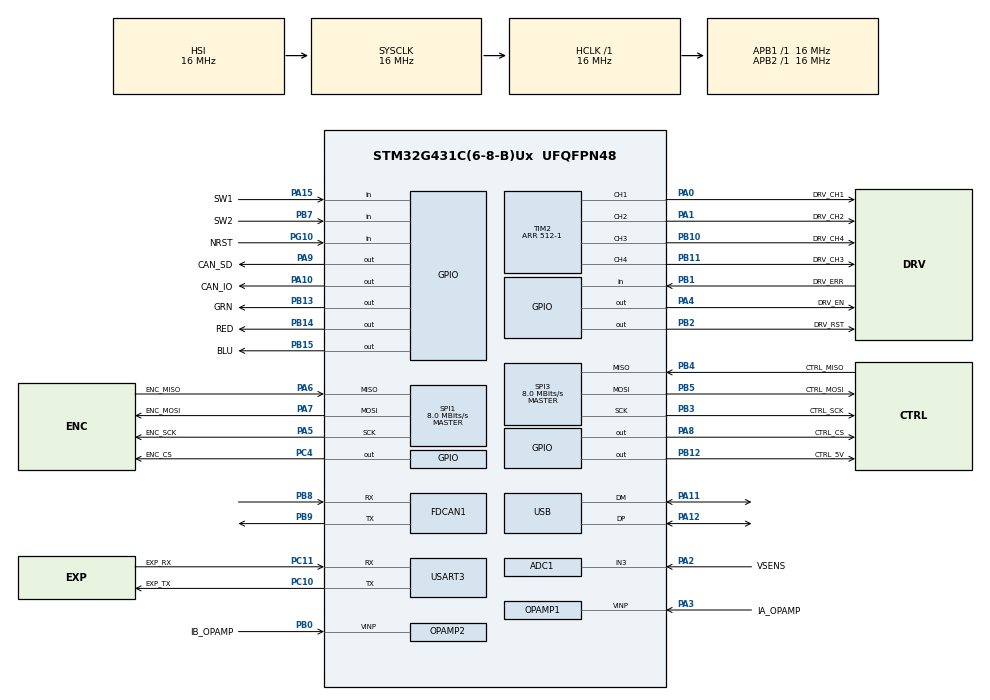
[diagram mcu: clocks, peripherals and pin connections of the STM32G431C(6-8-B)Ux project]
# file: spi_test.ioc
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ADC1.Channel-0\#ChannelRegularConversion=ADC_CHANNEL_3
ADC1.NbrOfConversionFlag=1
ADC1.OffsetNumber-0\#ChannelRegularConversion=ADC_OFFSET_NONE
ADC1.Rank-0\#ChannelRegularConversion=1
ADC1.SamplingTime-0\#ChannelRegularConversion=ADC_SAMPLETIME_2CYCLES_5
ADC1.master=1
FDCAN1.CalculateBaudRateNominal=200000
FDCAN1.CalculateTimeBitNominal=5000
FDCAN1.CalculateTimeQuantumNominal=1000.0
Mcu.Family=STM32G4
Mcu.Name=STM32G431C(6-8-B)Ux
Mcu.Package=UFQFPN48
NVIC.PriorityGroup=NVIC_PRIORITYGROUP_4
PA0.GPIO_Label=DRV_CH1
PA0.Signal=S_TIM2_CH1
PA1.GPIO_Label=DRV_CH2
PA1.Signal=S_TIM2_CH2
PA10.GPIO_Label=CAN_IO
PA10.Signal=GPIO_Output
PA11.Mode=Device
PA11.Signal=USB_DM
PA12.Mode=Device
PA12.Signal=USB_DP
PA13.GPIO_Label=SWDIO
PA13.Mode=Serial_Wire
PA13.Signal=SYS_JTMS-SWDIO
PA14.GPIO_Label=SWCLK
PA14.Mode=Serial_Wire
PA14.Signal=SYS_JTCK-SWCLK
PA15.GPIO_Label=SW1
PA15.Signal=GPIO_Input
PA2.GPIO_Label=VSENS
PA2.Mode=IN3-Single-Ended
PA2.Signal=ADC1_IN3
PA3.GPIO_Label=IA_OPAMP
PA3.Mode=Follower_Internally_Connected
PA3.Signal=OPAMP1_VINP
PA4.GPIO_Label=DRV_EN
PA4.PinState=GPIO_PIN_SET
PA4.Signal=GPIO_Output
PA5.GPIO_Label=ENC_SCK
PA5.Mode=Full_Duplex_Master
PA5.Signal=SPI1_SCK
PA6.GPIO_Label=ENC_MISO
PA6.Mode=Full_Duplex_Master
PA6.Signal=SPI1_MISO
PA7.GPIO_Label=ENC_MOSI
PA7.Mode=Full_Duplex_Master
PA7.Signal=SPI1_MOSI
PA8.GPIO_Label=CTRL_CS
PA8.Signal=GPIO_Output
PA9.GPIO_Label=CAN_SD
PA9.Signal=GPIO_Output
PB0.GPIO_Label=IB_OPAMP
PB0.Mode=Follower_Internally_Connected
PB0.Signal=OPAMP2_VINP
PB1.GPIO_Label=DRV_ERR
PB1.Signal=GPIO_Input
PB10.GPIO_Label=DRV_CH4
PB10.Signal=S_TIM2_CH3
PB11.GPIO_Label=DRV_CH3
PB11.Signal=S_TIM2_CH4
PB12.GPIO_Label=CTRL_5V
PB12.Signal=GPIO_Output
PB13.GPIO_Label=GRN
PB13.Signal=GPIO_Output
PB14.GPIO_Label=RED
PB14.Signal=GPIO_Output
PB15.GPIO_Label=BLU
PB15.Signal=GPIO_Output
PB2.GPIO_Label=DRV_RST
PB2.PinState=GPIO_PIN_SET
PB2.Signal=GPIO_Output
PB3.GPIO_Label=CTRL_SCK
PB3.Mode=Full_Duplex_Master
PB3.Signal=SPI3_SCK
PB4.GPIO_Label=CTRL_MISO
PB4.Mode=Full_Duplex_Master
PB4.Signal=SPI3_MISO
PB5.GPIO_Label=CTRL_MOSI
PB5.Mode=Full_Duplex_Master
PB5.Signal=SPI3_MOSI
PB7.GPIO_Label=SW2
PB7.Signal=GPIO_Input
PB8-BOOT0.Mode=FDCAN_Activate
PB8-BOOT0.Signal=FDCAN1_RX
PB9.Mode=FDCAN_Activate
PB9.Signal=FDCAN1_TX
PC10.GPIO_Label=EXP_TX
PC10.Mode=Asynchronous
PC10.Signal=USART3_TX
PC11.GPIO_Label=EXP_RX
PC11.Mode=Asynchronous
PC11.Signal=USART3_RX
PC4.GPIO_Label=ENC_CS
PC4.Signal=GPIO_Output
PF0-OSC_IN.GPIO_Label=HSE_IN
PF0-OSC_IN.Mode=HSE-External-Oscillator
PF0-OSC_IN.Signal=RCC_OSC_IN
PF1-OSC_OUT.GPIO_Label=HSE_OUT
PF1-OSC_OUT.Mode=HSE-External-Oscillator
PF1-OSC_OUT.Signal=RCC_OSC_OUT
PG10-NRST.GPIO_Label=NRST
PG10-NRST.Signal=GPIO_Input
ProjectManager.HeapSize=0x200
ProjectManager.StackSize=0x400
ProjectManager.TargetToolchain=STM32CubeIDE
RCC.ADC12Freq_Value=16000000
RCC.AHBFreq_Value=16000000
RCC.APB1Freq_Value=16000000
RCC.APB1TimFreq_Value=16000000
RCC.APB2Freq_Value=16000000
RCC.APB2TimFreq_Value=16000000
RCC.CortexFreq_Value=16000000
RCC.EXTERNAL_CLOCK_VALUE=12288000
RCC.HCLKFreq_Value=16000000
RCC.HSE_VALUE=8000000
RCC.HSI48_VALUE=48000000
RCC.HSI_VALUE=16000000
RCC.LSE_VALUE=32768
RCC.PLLN=12
RCC.PLLQ=RCC_PLLQ_DIV4
RCC.SYSCLKFreq_VALUE=16000000
RCC.USBFreq_Value=48000000
RCC.VCOOutputFreq_Value=192000000
SH.S_TIM2_CH1.0=TIM2_CH1,PWM Generation1 CH1
SH.S_TIM2_CH2.0=TIM2_CH2,PWM Generation2 CH2
SH.S_TIM2_CH3.0=TIM2_CH3,PWM Generation3 CH3
SH.S_TIM2_CH4.0=TIM2_CH4,PWM Generation4 CH4
SPI1.CalculateBaudRate=8.0 MBits/s
SPI1.Direction=SPI_DIRECTION_2LINES
SPI1.Mode=SPI_MODE_MASTER
SPI1.VirtualType=VM_MASTER
SPI3.CalculateBaudRate=8.0 MBits/s
SPI3.Direction=SPI_DIRECTION_2LINES
SPI3.Mode=SPI_MODE_MASTER
SPI3.VirtualType=VM_MASTER
TIM2.Channel-PWM\ Generation1\ CH1=TIM_CHANNEL_1
TIM2.Channel-PWM\ Generation2\ CH2=TIM_CHANNEL_2
TIM2.Channel-PWM\ Generation3\ CH3=TIM_CHANNEL_3
TIM2.Channel-PWM\ Generation4\ CH4=TIM_CHANNEL_4
TIM2.CounterMode=TIM_COUNTERMODE_CENTERALIGNED1
TIM2.PeriodNoDither=512-1
USART3.VirtualMode-Asynchronous=VM_ASYNC
VP_SYS_VS_DBSignals.Mode=DisableDeadBatterySignals
board=custom

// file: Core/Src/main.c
/* USER CODE BEGIN Header */
/**
  ******************************************************************************
  * @file           : main.c
  * @brief          : Main program body
  ******************************************************************************
  * @attention
  *
  * Copyright (c) 2024 STMicroelectronics.
  * All rights reserved.
  *
  * This software is licensed under terms that can be found in the LICENSE file
  * in the root directory of this software component.
  * If no LICENSE file comes with this software, it is provided AS-IS.
  *
  ******************************************************************************
  */
/* USER CODE END Header */
#include "main.h"
#include "adc.h"
#include "fdcan.h"
#include "opamp.h"
#include "spi.h"
#include "tim.h"
#include "usart.h"
#include "usb.h"
#include "gpio.h"

/* USER CODE BEGIN Includes */
#include "Arduino.h"
#include "SPI.h"
/* USER CODE END Includes */

void SystemClock_Config(void);

int main(void)
{

  /* MCU Configuration--------------------------------------------------------*/

  /* Reset of all peripherals, Initializes the Flash interface and the Systick. */
  HAL_Init();

  /* Configure the system clock */
  SystemClock_Config();

  /* Initialize all configured peripherals */
  MX_GPIO_Init();
  MX_FDCAN1_Init();
  MX_USART3_UART_Init();
  MX_USB_PCD_Init();
  MX_TIM2_Init();
  MX_SPI1_Init();
  MX_OPAMP1_Init();
  MX_SPI3_Init();
  MX_ADC1_Init();
  MX_OPAMP2_Init();

  /* Infinite loop */
  while (1)
  {

  }
}

void SystemClock_Config(void)
{
  RCC_OscInitTypeDef RCC_OscInitStruct = {0};
  RCC_ClkInitTypeDef RCC_ClkInitStruct = {0};

  /** Configure the main internal regulator output voltage
  */
  HAL_PWREx_ControlVoltageScaling(PWR_REGULATOR_VOLTAGE_SCALE1);

  /** Initializes the RCC Oscillators according to the specified parameters
  * in the RCC_OscInitTypeDef structure.
  */
  RCC_OscInitStruct.OscillatorType = RCC_OSCILLATORTYPE_HSI;
  RCC_OscInitStruct.HSIState = RCC_HSI_ON;
  RCC_OscInitStruct.HSICalibrationValue = RCC_HSICALIBRATION_DEFAULT;
  RCC_OscInitStruct.PLL.PLLState = RCC_PLL_ON;
  RCC_OscInitStruct.PLL.PLLSource = RCC_PLLSOURCE_HSI;
  RCC_OscInitStruct.PLL.PLLM = RCC_PLLM_DIV1;
  RCC_OscInitStruct.PLL.PLLN = 12;
  RCC_OscInitStruct.PLL.PLLP = RCC_PLLP_DIV2;
  RCC_OscInitStruct.PLL.PLLQ = RCC_PLLQ_DIV4;
  RCC_OscInitStruct.PLL.PLLR = RCC_PLLR_DIV2;
  if (HAL_RCC_OscConfig(&RCC_OscInitStruct) != HAL_OK)
  {
    Error_Handler();
  }

  /** Initializes the CPU, AHB and APB buses clocks
  */
  RCC_ClkInitStruct.ClockType = RCC_CLOCKTYPE_HCLK|RCC_CLOCKTYPE_SYSCLK
                              |RCC_CLOCKTYPE_PCLK1|RCC_CLOCKTYPE_PCLK2;
  RCC_ClkInitStruct.SYSCLKSource = RCC_SYSCLKSOURCE_HSI;
  RCC_ClkInitStruct.AHBCLKDivider = RCC_SYSCLK_DIV1;
  RCC_ClkInitStruct.APB1CLKDivider = RCC_HCLK_DIV1;
  RCC_ClkInitStruct.APB2CLKDivider = RCC_HCLK_DIV1;

  if (HAL_RCC_ClockConfig(&RCC_ClkInitStruct, FLASH_LATENCY_0) != HAL_OK)
  {
    Error_Handler();
  }
}

void Error_Handler(void)
{
  __disable_irq();
  while (1)
  {
  }
}
